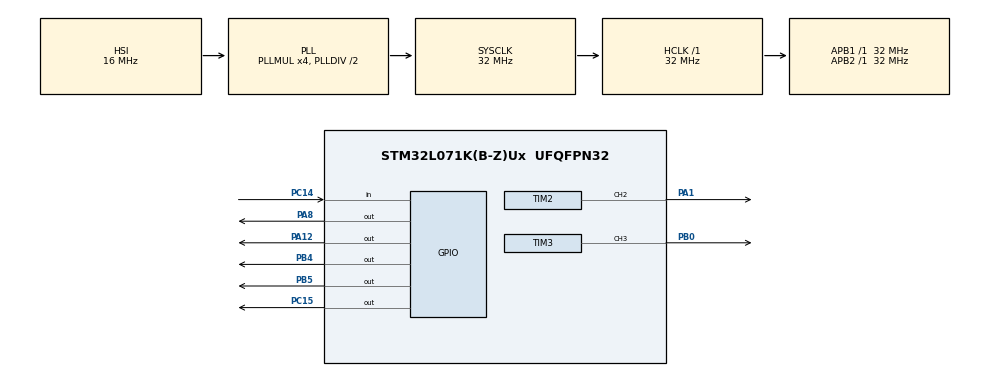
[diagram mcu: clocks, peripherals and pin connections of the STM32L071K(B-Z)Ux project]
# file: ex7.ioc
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Mcu.Family=STM32L0
Mcu.Name=STM32L071K(B-Z)Ux
Mcu.Package=UFQFPN32
NVIC.TIM2_IRQn=true\:0\:0\:false\:false\:true\:true\:true
NVIC.TIM3_IRQn=true\:0\:0\:false\:false\:true\:true\:true
PA1.Signal=S_TIM2_CH2
PA12.GPIO_ModeDefaultOutputPP=GPIO_MODE_OUTPUT_PP
PA12.GPIO_PuPd=GPIO_PULLDOWN
PA12.PinState=GPIO_PIN_RESET
PA12.Signal=GPIO_Output
PA13.Mode=Serial_Wire
PA13.Signal=SYS_SWDIO
PA14.Mode=Serial_Wire
PA14.Signal=SYS_SWCLK
PA8.Signal=GPIO_Output
PB0.GPIO_PuPd=GPIO_PULLUP
PB0.GPIO_Speed=GPIO_SPEED_FREQ_VERY_HIGH
PB0.Signal=S_TIM3_CH3
PB4.Signal=GPIO_Output
PB5.Signal=GPIO_Output
PC14-OSC32_IN.Signal=GPIO_Input
PC15-OSC32_OUT.Signal=GPIO_Output
ProjectManager.HeapSize=0x200
ProjectManager.StackSize=0x400
ProjectManager.TargetToolchain=MDK-ARM V5
RCC.AHBFreq_Value=32000000
RCC.APB1Freq_Value=32000000
RCC.APB1TimFreq_Value=32000000
RCC.APB2Freq_Value=32000000
RCC.APB2TimFreq_Value=32000000
RCC.HCLKFreq_Value=32000000
RCC.HSI16_VALUE=16000000
RCC.HSI_VALUE=16000000
RCC.LSE_VALUE=32768
RCC.MSI_VALUE=2097000
RCC.PLLMUL=RCC_PLLMUL_4
RCC.SYSCLKFreq_VALUE=32000000
RCC.SYSCLKSource=RCC_SYSCLKSOURCE_PLLCLK
RCC.VCOOutputFreq_Value=64000000
SH.S_TIM2_CH2.0=TIM2_CH2,PWM Generation2 CH2
SH.S_TIM3_CH3.0=TIM3_CH3,PWM Generation3 CH3
TIM2.AutoReloadPreload=TIM_AUTORELOAD_PRELOAD_DISABLE
TIM2.Channel-PWM\ Generation2\ CH2=TIM_CHANNEL_2
TIM2.Period=999
TIM2.Prescaler=31
TIM3.AutoReloadPreload=TIM_AUTORELOAD_PRELOAD_DISABLE
TIM3.Channel-PWM\ Generation3\ CH3=TIM_CHANNEL_3
TIM3.OCMode_PWM-PWM\ Generation3\ CH3=TIM_OCMODE_PWM2
TIM3.OCPolarity_3=TIM_OCPOLARITY_LOW
TIM3.Period=999
TIM3.Prescaler=31
TIM3.TIM_MasterOutputTrigger=TIM_TRGO_OC3REF
VP_TIM2_VS_ClockSourceINT.Mode=Internal
VP_TIM3_VS_ClockSourceINT.Mode=Internal
board=custom

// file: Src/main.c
/* USER CODE BEGIN Header */
/**
  ******************************************************************************
  * @file           : main.c
  * @brief          : Main program body
  ******************************************************************************
  * @attention
  *
  * <h2><center>&copy; Copyright (c) 2019 STMicroelectronics.
  * All rights reserved.</center></h2>
  *
  * This software component is licensed by ST under BSD 3-Clause license,
  * the "License"; You may not use this file except in compliance with the
  * License. You may obtain a copy of the License at:
  *                        opensource.org/licenses/BSD-3-Clause
  *
  ******************************************************************************
  */
/* USER CODE END Header */

#include "main.h"
#include "tim.h"
#include "gpio.h"

void SystemClock_Config(void);

int main(void)
{
  /* USER CODE BEGIN 1 */
	int a=0;

  /* USER CODE END 1 */

  /* MCU Configuration--------------------------------------------------------*/

  /* Reset of all peripherals, Initializes the Flash interface and the Systick. */
  HAL_Init();

  /* Configure the system clock */
  SystemClock_Config();

  /* Initialize all configured peripherals */
  MX_GPIO_Init();
  MX_TIM3_Init();
  MX_TIM2_Init();
  /* USER CODE BEGIN 2 */
    Task_BrdInit();
		HAL_TIM_PWM_Start(&htim3, TIM_CHANNEL_3);
		HAL_TIM_PWM_Start(&htim2, TIM_CHANNEL_2);
//		HAL_TIM_Base_Start(&htim3);
  /* USER CODE END 2 */

  /* Infinite loop */
  /* USER CODE BEGIN WHILE */
    while (1)
    {
      Task_Main();

//			for(a=0;a<=1000;a++)
//			{
//				__HAL_TIM_SET_COMPARE(&htim3,TIM_CHANNEL_3,a);//����ռ�ձ�
//				HAL_Delay(1);
//			}
//			for(a=1000;a>=0;a--)
//			{
//				__HAL_TIM_SET_COMPARE(&htim3,TIM_CHANNEL_3,a);
//				HAL_Delay(1);
//			}
//
//			for(a=0;a<=1000;a++)
//			{
//				__HAL_TIM_SET_COMPARE(&htim2,TIM_CHANNEL_2,a);//����ռ�ձ�
//				HAL_Delay(1);
//			}
//			for(a=1000;a>=0;a--)
//			{
//				__HAL_TIM_SET_COMPARE(&htim2,TIM_CHANNEL_2,a);
//				HAL_Delay(10);
//			}

//			__HAL_TIM_SET_COMPARE(&htim2,TIM_CHANNEL_2,500);
//			HAL_Delay(1000);
//			__HAL_TIM_SET_COMPARE(&htim2,TIM_CHANNEL_2,500);
//			HAL_Delay(1000);
//			__HAL_TIM_SET_COMPARE(&htim2,TIM_CHANNEL_2,980);
//			HAL_Delay(1000);
    /* USER CODE END WHILE */

    }
}

void SystemClock_Config(void)
{
  RCC_OscInitTypeDef RCC_OscInitStruct = {0};
  RCC_ClkInitTypeDef RCC_ClkInitStruct = {0};

  /** Configure the main internal regulator output voltage
  */
  __HAL_PWR_VOLTAGESCALING_CONFIG(PWR_REGULATOR_VOLTAGE_SCALE1);
  /** Initializes the CPU, AHB and APB busses clocks
  */
  RCC_OscInitStruct.OscillatorType = RCC_OSCILLATORTYPE_HSI;
  RCC_OscInitStruct.HSIState = RCC_HSI_ON;
  RCC_OscInitStruct.HSICalibrationValue = RCC_HSICALIBRATION_DEFAULT;
  RCC_OscInitStruct.PLL.PLLState = RCC_PLL_ON;
  RCC_OscInitStruct.PLL.PLLSource = RCC_PLLSOURCE_HSI;
  RCC_OscInitStruct.PLL.PLLMUL = RCC_PLLMUL_4;
  RCC_OscInitStruct.PLL.PLLDIV = RCC_PLLDIV_2;
  if (HAL_RCC_OscConfig(&RCC_OscInitStruct) != HAL_OK)
  {
    Error_Handler();
  }
  /** Initializes the CPU, AHB and APB busses clocks
  */
  RCC_ClkInitStruct.ClockType = RCC_CLOCKTYPE_HCLK|RCC_CLOCKTYPE_SYSCLK
                              |RCC_CLOCKTYPE_PCLK1|RCC_CLOCKTYPE_PCLK2;
  RCC_ClkInitStruct.SYSCLKSource = RCC_SYSCLKSOURCE_PLLCLK;
  RCC_ClkInitStruct.AHBCLKDivider = RCC_SYSCLK_DIV1;
  RCC_ClkInitStruct.APB1CLKDivider = RCC_HCLK_DIV1;
  RCC_ClkInitStruct.APB2CLKDivider = RCC_HCLK_DIV1;

  if (HAL_RCC_ClockConfig(&RCC_ClkInitStruct, FLASH_LATENCY_1) != HAL_OK)
  {
    Error_Handler();
  }
}

void Error_Handler(void)
{
}

/************************ (C) COPYRIGHT STMicroelectronics *****END OF FILE****/
